# MCXC444 register map
Vendor: NXP Semiconductors; Series: MCX; File version: 1.6
CPU: CM0PLUS r0p0, little endian, no MPU, no FPU, VTOR, 2 interrupt priority bits
Registers are 32-bit, read-write, reset 0x0 unless marked. A register's access mark holds for its fields unless they carry their own. Offsets are from the block's base; [hi:lo] are bit positions.

## PMC — Power Management Controller
Base 0x4007D000; register names take the prefix PMC_
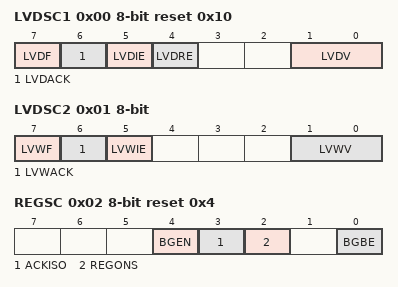
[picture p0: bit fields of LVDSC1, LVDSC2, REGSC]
0x00 LVDSC1 8-bit reset 0x10 — Low Voltage Detect Status And Control 1 register
  [7] LVDF ro — Low-Voltage Detect Flag
    0=b0 (Low-voltage event not detected); 1=b1 (Low-voltage event detected)
  [6] LVDACK — Low-Voltage Detect Acknowledge
  [5] LVDIE — Low-Voltage Detect Interrupt Enable
    0=b0 (Hardware interrupt disabled (use polling)); 1=b1 (Request a hardware interrupt when LVDF = 1)
  [4] LVDRE — Low-Voltage Detect Reset Enable
    0=b0 (LVDF does not generate hardware resets); 1=b1 (Force an MCU reset when LVDF = 1)
  [1:0] LVDV — Low-Voltage Detect Voltage Select
    0=b00 (Low trip point selected (V LVD = V LVDL )); 1=b01 (High trip point selected (V LVD = V LVDH ))
0x01 LVDSC2 8-bit — Low Voltage Detect Status And Control 2 register
  [7] LVWF ro — Low-Voltage Warning Flag
    0=b0 (Low-voltage warning event not detected); 1=b1 (Low-voltage warning event detected)
  [6] LVWACK — Low-Voltage Warning Acknowledge
  [5] LVWIE — Low-Voltage Warning Interrupt Enable
    0=b0 (Hardware interrupt disabled (use polling)); 1=b1 (Request a hardware interrupt when LVWF = 1)
  [1:0] LVWV — Low-Voltage Warning Voltage Select
    0=b00 (Low trip point selected (VLVW = VLVW1)); 1=b01 (Mid 1 trip point selected (VLVW = VLVW2)); 2=b10 (Mid 2 trip point selected (VLVW = VLVW3)); 3=b11 (High trip point selected (VLVW = VLVW4))
0x02 REGSC 8-bit reset 0x4 — Regulator Status And Control register
  [4] BGEN — Bandgap Enable In VLPx Operation
    0=b0 (Bandgap voltage reference is disabled in VLPx , LLS , and VLLSx modes.); 1=b1 (Bandgap voltage reference is enabled in VLPx , LLS , and VLLSx modes.)
  [3] ACKISO — Acknowledge Isolation
    0=b0 (Peripherals and I/O pads are in normal run state.); 1=b1 (Certain peripherals and I/O pads are in an isolated and latched state.)
  [2] REGONS ro — Regulator In Run Regulation Status
    0=b0 (Regulator is in stop regulation or in transition to/from it); 1=b1 (Regulator is in run regulation)
  [0] BGBE — Bandgap Buffer Enable
    0=b0 (Bandgap buffer not enabled); 1=b1 (Bandgap buffer enabled)

## SMC — System Mode Controller
Base 0x4007E000; register names take the prefix SMC_
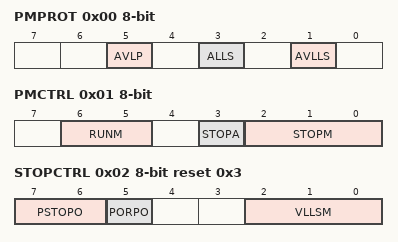
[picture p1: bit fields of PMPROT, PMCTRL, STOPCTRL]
0x00 PMPROT 8-bit — Power Mode Protection register
  [5] AVLP — Allow Very-Low-Power Modes
    0=b0 (VLPR, VLPW, and VLPS are not allowed.); 1=b1 (VLPR, VLPW, and VLPS are allowed.)
  [3] ALLS — Allow Low-Leakage Stop Mode
    0=b0 (LLS is not allowed); 1=b1 (LLS is allowed)
  [1] AVLLS — Allow Very-Low-Leakage Stop Mode
    0=b0 (Any VLLSx mode is not allowed); 1=b1 (Any VLLSx mode is allowed)
0x01 PMCTRL 8-bit — Power Mode Control register
  [6:5] RUNM — Run Mode Control
    0=b00 (Normal Run mode (RUN)); 2=b10 (Very-Low-Power Run mode (VLPR))
  [3] STOPA ro — Stop Aborted
    0=b0 (The previous stop mode entry was successsful.); 1=b1 (The previous stop mode entry was aborted.)
  [2:0] STOPM — Stop Mode Control
    0=b000 (Normal Stop (STOP)); 2=b010 (Very-Low-Power Stop (VLPS)); 3=b011 (Low-Leakage Stop (LLS)); 4=b100 (Very-Low-Leakage Stop (VLLSx)); 6=b110 (Reseved)
0x02 STOPCTRL 8-bit reset 0x3 — Stop Control Register
  [7:6] PSTOPO — Partial Stop Option
    0=b00 (STOP - Normal Stop mode); 1=b01 (PSTOP1 - Partial Stop with both system and bus clocks disabled); 2=b10 (PSTOP2 - Partial Stop with system clock disabled and bus clock enabled)
  [5] PORPO — POR Power Option
    0=b0 (POR detect circuit is enabled in VLLS0); 1=b1 (POR detect circuit is disabled in VLLS0)
  [2:0] VLLSM — VLLS Mode Control
    0=b000 (VLLS0); 1=b001 (VLLS1); 3=b011 (VLLS3)
0x03 PMSTAT 8-bit ro reset 0x1 — Power Mode Status register
  [7:0] PMSTAT — Power Mode Status
